# DWC_USB3 register map
Vendor: Texas Instruments
Registers are 32-bit, read-write, reset 0x0 unless marked. A register's access mark holds for its fields unless they carry their own. Offsets are as the file gives them; [hi:lo] are bit positions; {n}, {i} and the like mark numbered series; 'fields as' and 'values as' point back to an identical list.

## DWC_USB3 (part 2 of 2)
0xC188 USBOTGSS_GPRTBIMAP_FSLO access per field — Global port to USB instance mapping register, full/low-speed, low bits [31:0]
  [3:0] BINUM1 rw — FS USB instance number for port number 1 Application-programmable ID field
0xC18C USBOTGSS_GPRTBIMAP_FSHI ro — Global port to USB instance mapping register, full/low-speed, high bits [63:32]
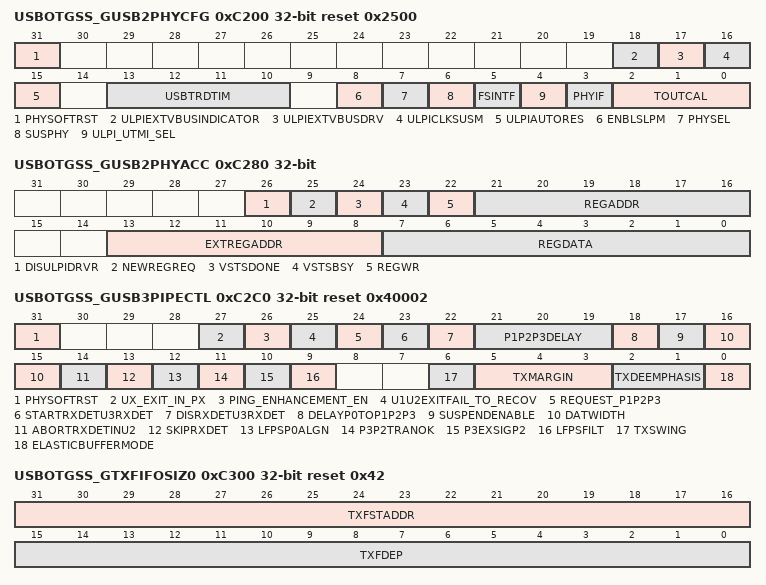
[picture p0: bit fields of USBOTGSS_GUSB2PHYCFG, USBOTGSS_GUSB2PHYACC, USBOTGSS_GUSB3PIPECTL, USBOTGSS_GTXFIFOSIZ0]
0xC200 USBOTGSS_GUSB2PHYCFG access per field reset 0x2500 — Global USB2 (UTMI/ULPI) PHY configuration
  [31] PHYSOFTRST rw — PHY Soft Reset. Active-high, fully static software reset for UTMI USB2 transceiver.
    0=inactive (Reset inactive.); 1=active (Reset active.)
  [18] ULPIEXTVBUSINDICATOR rw — ULPI External VBUS Indicator Indicates the ULPI PHY VBUS over-current indicator.
    0=int (PHY uses an internal VBUS valid comparator.); 1=ext (PHY uses an external VBUS valid comparator.)
  [17] ULPIEXTVBUSDRV rw — ULPI External VBUS Drive Selects supply source to drive 5V on VBUS, in the ULPI PHY.
    0=int (PHY drives VBUS with internal charge pump); 1=ext (PHY drives VBUS with an external supply.)
  [16] ULPICLKSUSM rw — Sets the ClockSuspendM bit in the Interface Control register on the ULPI PHY. Applicable only in serial FS/LS or Carkit modes. NOT APPLICABLE
  [15] ULPIAUTORES rw — ULPI Auto Resume. Sets the AutoResume bit in Interface Control register on the ULPI PHY.
    0=no (PHY does not use the AutoResume feature.); 1=auto (PHY uses the AutoResume feature.)
  [13:10] USBTRDTIM rw — USB 2.0 Turnaround Time, in PHY clock cycles. Specifies the response time for a MAC request to the Packet FIFO Controller (PFC) to fetch data from the DFIFO (SPRAM).
  [8] ENBLSLPM rw — Enable UTMI Sleep. Controls assertion of utmi_sleep_n, utmi_l1_suspend_n outputs to the PHY when in the L1 state.
    0=no (utmi_sleep_n, utmi_l1_suspend_n assertion from the core not transferred to the external PHY.); 1=yes (utmi_sleep_n, utmi_l1_suspend_n assertion from the core transferred to the external PHY.)
  [7] PHYSEL ro — PHY Select. (HS vs. serial): Unused, since serial PHY is not supported.
  [6] SUSPHY rw — Suspend enable for USB2.0 HS/FS/LS PHY (ULPI or UTMI). Set to 1 only after core initialization is complete.
    0=USB2.0 PHY not placed in Suspend mode; 1=USB2.0 PHY enters Suspend mode if port is suspended or unused
  [5] FSINTF ro — Full-Speed Serial Interface Select. UNUSED.
  [4] ULPI_UTMI_SEL rw — ULPI or UTMI+ Select
    0=UTMI+ Interface; 1=ULPI Interface
  [3] PHYIF rw — PHY Interface. DO NOT USE. If UTMI+ is selected, configures 8- or 16-bit interface. If ULPI is selected, configures SDR or DDR mode.
    0=zero (8-bit UTMI @60 MHz / SDR (12-pin) ULPI); 1=one (16-bit UTMI @30 MHz, not supported / DDR (8-pin) ULPI, not supported)
  [2:0] TOUTCAL rw — HS/FS Timeout Calibration. The number of PHY clocks, as indicated by the application in this field, is multiplied by a bit-time factor; this factor is added to the high-speed/full-speed interpacket timeout duration in the core to account for additional delays introduced by the PHY. This may be required, since the delay introduced by the PHY in generating the linestate condition may vary among PHYs. The USB standard timeout value for high-speed operation is 736 to 816 (inclusive) bit times. The USB standard timeout value for full-speed operation is 16 to 18 (inclusive) bit times. The application must program this field based on the speed of connection. The number of bit times added per PHY clock are: High-speed operation: 8 bit times per 60-MHz PHY clock cycle Full-speed operation: (depending on clock speed) 0.2 bit times per 60-MHz PHY clock cycle 0.25 bit times per 48-MHz PHY clock cycle
0xC280 USBOTGSS_GUSB2PHYACC access per field — Global USB2 PHY access
  [26] DISULPIDRVR ro — Disable ULPI drivers, for carkit mode. Auto-cleared. NOT USED.
  [25] NEWREGREQ rw — New register request. Auto-cleared.
    0=No_action; 1=Request_new_register_access; 1=Access_request_pending; 0=No_request_pending
  [24] VSTSDONE ro — VStatus Done
    1=access_is_done; 0=NEWREGREQ_0 (Application has set the NEWREGREQ bit, access is not done.)
  [23] VSTSBSY ro — VStatus busy
    1=Access_is_in_progress; 0=Access_is_done
  [22] REGWR rw — Register write
    0=Read; 1=Write
  [21:16] REGADDR rw — Register address ULPI PHY register address for immediate PHY register set access. Set to 6'h2F for extended PHY register set access.
  [13:8] EXTREGADDR rw — ULPI: PHY extended register address. UTMI+: Unused
  [7:0] REGDATA rw — Register data (read and write data)
0xC2C0 USBOTGSS_GUSB3PIPECTL access per field reset 0x40002 — Global USB3 PIPE control
  [31] PHYSOFTRST rw — PHY Soft Reset. Active-high, fully static software reset for PIPE USB3 transceiver.
    0=inactive (Reset inactive.); 1=active (Reset active.)
  [27] UX_EXIT_IN_PX rw — Workaround for SS PHY injecting a glitch on RxElecIdle while receiving Ux exit LFPS, and PowerDown change is in progress.
    0=default (U1/U2/U3 exit done in PHY power state P0); 1=wa (U1/U2/U3 exit done in PHY power state P1/P2/P3 respectively)
  [26] PING_ENHANCEMENT_EN rw — Ping Enhancement Enable: Extended downstream port U1 ping receive timeout. Invalid for Upstream port.
    0=default (U1 ping rx timeout is 300 ms (default)); 1=U1 ping rx timeout extended to 500 ms
  [25] U1U2EXITFAIL_TO_RECOV rw — Enhancement to prevent interoperability issue in case of incorrect LFPS handshake by the remote link.
    0=default (LTSSM goes to SS Inactive when U1/U2 LFPS handshake fails (default)); 1=enhanced (LTSSM goes to Recovery when U1/U2 LFPS handshake fails, and to SS.Inactive only if recovery fails.)
  [24] REQUEST_P1P2P3 rw — Control the systematic request of P1/P2/P3 for U1/U2/U3
    0=none (No P1/P2/P3 change request upon immediate Ux exit (remotely or locally initiated)); 1=Always request transition from P0 to P1/P2/P3 on PHY during transition from U0 to U1/U2/U3 on USB
  [23] STARTRXDETU3RXDET rw — Manual control for periodic Rx detection required in U3 and Rx.Detect, host mode.
    0=noop (No action); 1=detect (Trigger immediate Rx detection on transmitter.)
  [22] DISRXDETU3RXDET rw — Disable the HW-scheduled periodic Rx detection required in U3 and SS.Disabled, for host mode.
    0=Auto (Rx detection is HW-scheduled every 12/100 ms when in SS.Disabled / U3 LTSSM state, respectively. This requires the suspend clock to run permanently.); 1=Manual (HW-scheduled Rx detection is disabled, and must be SW-controlled using DoRxDetect.)
  [21:19] P1P2P3DELAY rw — If DelayP0toP1P2P3=1, delays the transition to P1/P2/P3 when entering U1/U2/U3 until P1P2P3Delay*8b10b errors occur, or RxValid=0 on PIPE.
  [18] DELAYP0TOP1P2P3 rw — Delay PHY change from P0 to P1/P2/P3 when link state changes from U0 to U1/U2/U3, respectively.
    0=dis (When entering U1/U2/U3, transition to P1/P2/P3 without checking RxElecIlde, RxValid on PIPE.); 1=en (When entering U1/U2/U3, delay the transition to P1/P2/P3 until RxElecIlde=1, RxValid=0 on PIPE)
  [17] SUSPENDENABLE rw — Suspend Enable for USB3.0 SS PHY. Set to 1 only after core initialization is complete.
    0=USB3.0 PHY not placed in Suspend mode; 1=USB 3.0 PHY enters Suspend mode when conditions are valid
  [16:15] DATWIDTH ro — PIPE Data Width (input from phy: refer to PIPE standard) Field updated to the input's value immediately after reset.
    2=DATWIDTH_2_r (PIPE data is 8 bit @500 MHz); 1=DATWIDTH_1_r (PIPE data is 16 bit @250 MHz); 0=DATWIDTH_0_r (PIPE data is 32 bit @125 MHz)
  [14] ABORTRXDETINU2 rw — Abort Rx Detect in U2. For Downstream port only.
    0=no_abort (Receiver detection not aborted); 1=abort (When in U2, receiver detection will be aborted if U2 exit LFPS is received.)
  [13] SKIPRXDET rw — Skip Rx Detect. When set, the core skips Rx Detection if PIPE signal 'RxElecIdle' is low. Skip is defined as waiting for the appropriate timeout, then repeating the operation.
  [12] LFPSP0ALGN rw — LFPS P0 Align. When set to 1: - The core deasserts LFPS transmission on the clock edge that it requests PHY power state 0 when exiting U1, U2, or U3 low power states. Otherwise, LFPS transmission is asserted one clock earlier. - The core requests symbol transmission two pipe_rx_pclks periods after the PHY asserts PhyStatus as a result of the PHY switching from P1 or P2 state to P0 state.
    0=def (Default); 1=align (DO NOT USE)
  [11] P3P2TRANOK rw — P3-to-P2 Transitions OK
    0=notset (P0 is always entered as an intermediate state during transitions between P2 and P3, as defined in the PIPE specification.); 1=set (Core transitions directly from PHY power state P2 to P3 or from state P3 to P2. Illegal as per PIPE, use only if PHY cannot do LFPS in P3.)
  [10] P3EXSIGP2 rw — PHY power state behaviour upon U3 exit handshake.
    0=Default behaviour; 1=p2 (Go to P2 before attempting a U3 exit handshake.)
  [9] LFPSFILT rw — LFPS Filter. When set, filter LFPS reception with PIPE 'RxValid' signal in PHY power state P0, that is, ignore LFPS reception from the PHY unless both PIPE signals 'RxElecIdle' and 'RxValid' are deasserted.
  [6] TXSWING rw — Tx Swing (output to PHY: refer to PIPE standard)
  [5:3] TXMARGIN rw — Tx Margin[2:0] (output to PHY: refer to PIPE standard)
  [2:1] TXDEEMPHASIS rw — Tx Deemphasis (output to PHY: refer to PIPE standard) The value driven to the PHY is controlled by the LTSSM during USB3 Compliance mode.
  [0] ELASTICBUFFERMODE rw — Elastic Buffer Mode (output to PHY: refer to PIPE standard)
0xC300 USBOTGSS_GTXFIFOSIZ0 reset 0x42 — Global Transmit FIFO Size 0: FIFO mapping in RAM1, from staddr to (staddr+dep-1)
  [31:16] TXFSTADDR — Transmit FIFO RAM start address, in 64-bit RAM words.
    0=Minimum_(RAM1_base); 0x760=Maximum_(up_to_RAM1_depth_-_32)
  [15:0] TXFDEP — Transmit FIFO depth, in 64-bit RAM words.
    0x780=Maximum_depth_(the_whole_buffer); 32=Minimum_depth
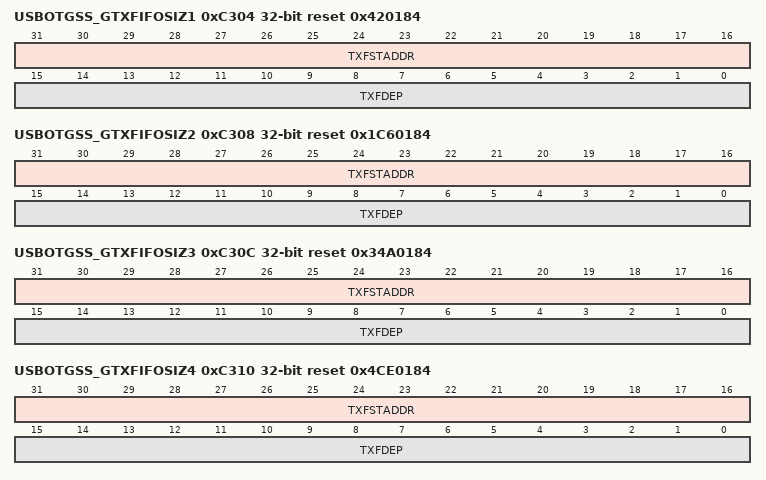
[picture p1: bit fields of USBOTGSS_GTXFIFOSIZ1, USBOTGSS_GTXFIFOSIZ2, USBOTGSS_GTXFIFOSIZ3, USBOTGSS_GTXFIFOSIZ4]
0xC304 USBOTGSS_GTXFIFOSIZ1 reset 0x420184 — Global Transmit FIFO Size 1: FIFO mapping in RAM1, from staddr to (staddr+dep-1)
  fields as USBOTGSS_GTXFIFOSIZ0
0xC308 USBOTGSS_GTXFIFOSIZ2 reset 0x1C60184 — Global Transmit FIFO Size 2: FIFO mapping in RAM1, from staddr to (staddr+dep-1)
  fields as USBOTGSS_GTXFIFOSIZ0
0xC30C USBOTGSS_GTXFIFOSIZ3 reset 0x34A0184 — Global Transmit FIFO Size 3: FIFO mapping in RAM1, from staddr to (staddr+dep-1)
  fields as USBOTGSS_GTXFIFOSIZ0
0xC310 USBOTGSS_GTXFIFOSIZ4 reset 0x4CE0184 — Global Transmit FIFO Size 4: FIFO mapping in RAM1, from staddr to (staddr+dep-1)
  fields as USBOTGSS_GTXFIFOSIZ0
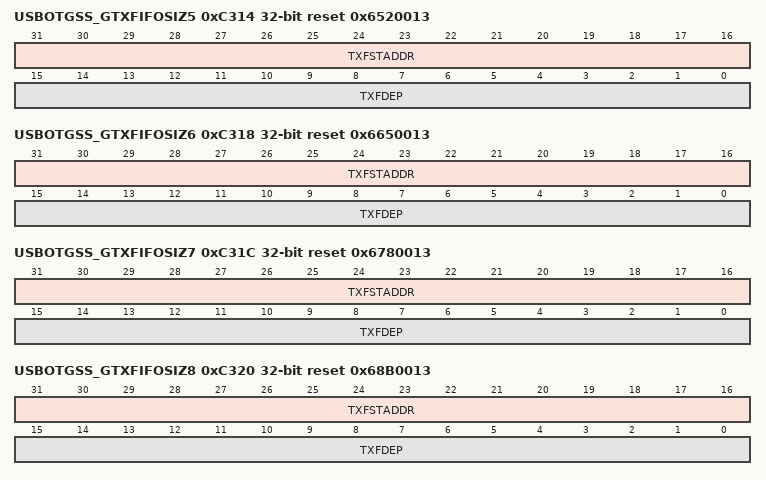
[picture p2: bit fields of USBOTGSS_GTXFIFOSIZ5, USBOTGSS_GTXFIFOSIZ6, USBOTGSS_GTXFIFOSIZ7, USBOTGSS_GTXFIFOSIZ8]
0xC314 USBOTGSS_GTXFIFOSIZ5 reset 0x6520013 — Global Transmit FIFO Size 5: FIFO mapping in RAM1, from staddr to (staddr+dep-1)
  fields as USBOTGSS_GTXFIFOSIZ0
0xC318 USBOTGSS_GTXFIFOSIZ6 reset 0x6650013 — Global Transmit FIFO Size 6: FIFO mapping in RAM1, from staddr to (staddr+dep-1)
  fields as USBOTGSS_GTXFIFOSIZ0
0xC31C USBOTGSS_GTXFIFOSIZ7 reset 0x6780013 — Global Transmit FIFO Size 7: FIFO mapping in RAM1, from staddr to (staddr+dep-1)
  fields as USBOTGSS_GTXFIFOSIZ0
0xC320 USBOTGSS_GTXFIFOSIZ8 reset 0x68B0013 — Global Transmit FIFO Size 8: FIFO mapping in RAM1, from staddr to (staddr+dep-1)
  fields as USBOTGSS_GTXFIFOSIZ0
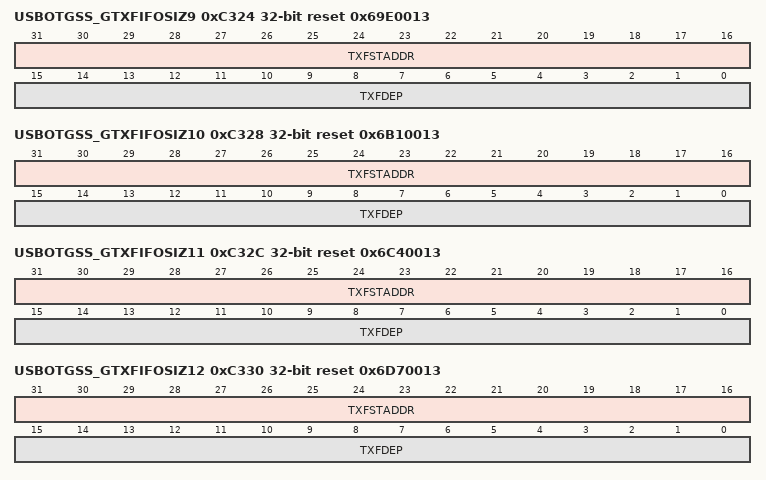
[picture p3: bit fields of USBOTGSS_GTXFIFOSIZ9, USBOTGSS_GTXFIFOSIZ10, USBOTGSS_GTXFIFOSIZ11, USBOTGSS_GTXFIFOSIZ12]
0xC324 USBOTGSS_GTXFIFOSIZ9 reset 0x69E0013 — Global Transmit FIFO Size 9: FIFO mapping in RAM1, from staddr to (staddr+dep-1)
  fields as USBOTGSS_GTXFIFOSIZ0
0xC328 USBOTGSS_GTXFIFOSIZ10 reset 0x6B10013 — Global Transmit FIFO Size 10: FIFO mapping in RAM1, from staddr to (staddr+dep-1)
  fields as USBOTGSS_GTXFIFOSIZ0
0xC32C USBOTGSS_GTXFIFOSIZ11 reset 0x6C40013 — Global Transmit FIFO Size 11: FIFO mapping in RAM1, from staddr to (staddr+dep-1)
  fields as USBOTGSS_GTXFIFOSIZ0
0xC330 USBOTGSS_GTXFIFOSIZ12 reset 0x6D70013 — Global Transmit FIFO Size 12: FIFO mapping in RAM1, from staddr to (staddr+dep-1)
  fields as USBOTGSS_GTXFIFOSIZ0
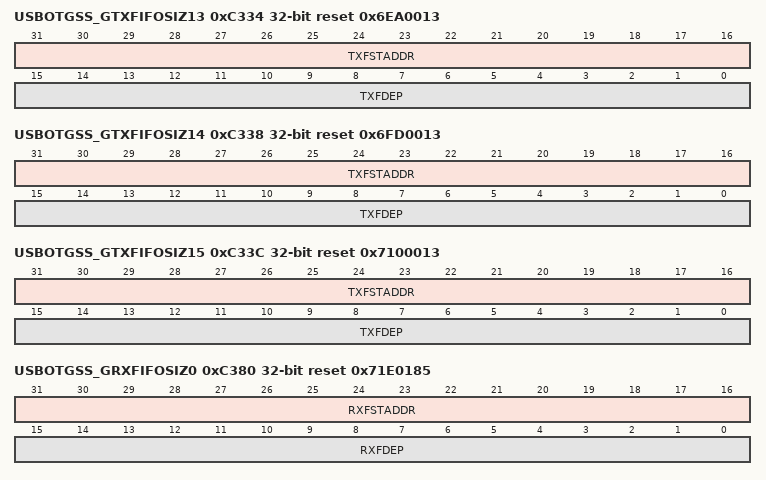
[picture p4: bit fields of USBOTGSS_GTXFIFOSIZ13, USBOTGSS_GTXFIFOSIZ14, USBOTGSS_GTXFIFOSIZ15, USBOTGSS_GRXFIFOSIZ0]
0xC334 USBOTGSS_GTXFIFOSIZ13 reset 0x6EA0013 — Global Transmit FIFO Size 13: FIFO mapping in RAM1, from staddr to (staddr+dep-1)
  fields as USBOTGSS_GTXFIFOSIZ0
0xC338 USBOTGSS_GTXFIFOSIZ14 reset 0x6FD0013 — Global Transmit FIFO Size 14: FIFO mapping in RAM1, from staddr to (staddr+dep-1)
  fields as USBOTGSS_GTXFIFOSIZ0
0xC33C USBOTGSS_GTXFIFOSIZ15 reset 0x7100013 — Global Transmit FIFO Size 15: FIFO mapping in RAM1, from staddr to (staddr+dep-1)
  fields as USBOTGSS_GTXFIFOSIZ0
0xC380 USBOTGSS_GRXFIFOSIZ0 reset 0x71E0185 — Global Receive FIFO Size 0: FIFO mapping in RAM0, from staddr to (staddr+dep-1)
  [31:16] RXFSTADDR — Receive FIFO RAM Start Address, in 64-bit RAM words.
    0=min (Minimum (RAM0 base)); 0x3C2=max (Maximum (base of descriptor cache in RAM0 - 32))
  [15:0] RXFDEP — Receive FIFO Depth, in 64-bit RAM words
    32=min (Minimum depth); 0x3E2=max (Maximum depth (the whole buffer))
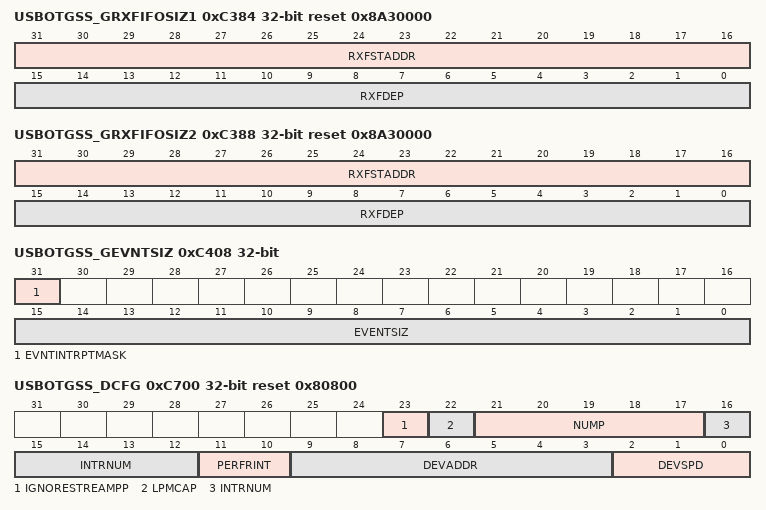
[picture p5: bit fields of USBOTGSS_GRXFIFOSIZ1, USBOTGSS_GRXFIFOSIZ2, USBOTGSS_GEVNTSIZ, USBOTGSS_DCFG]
0xC384 USBOTGSS_GRXFIFOSIZ1 reset 0x8A30000 — Global receive FIFO size 1: FIFO mapping in RAM0, from staddr to (staddr+dep-1)
  fields as USBOTGSS_GRXFIFOSIZ0
0xC388 USBOTGSS_GRXFIFOSIZ2 reset 0x8A30000 — Global receive FIFO size 2: FIFO mapping in RAM0, from staddr to (staddr+dep-1)
  fields as USBOTGSS_GRXFIFOSIZ0
0xC400 USBOTGSS_GEVNTADRLO — Global event address: Lower 32 bits of start address of the external memory for the event buffer. During operation, hardware does not update this address.
  [31:0] EVNTADRLO — EVNTADR[31:0]
0xC404 USBOTGSS_GEVNTADRHI — Global event address: Upper 32 bits of start address of the external memory for the event buffer. During operation, hardware does not update this address.
  [31:0] EVNTADRHI — EVNTADR[64:32]
0xC408 USBOTGSS_GEVNTSIZ access per field — Global event buffer size
  [31] EVNTINTRPTMASK rw — Event interrupt mask Prevents the interrupt from being generated when set to 1 The events are queued wven when the mask is set.
  [15:0] EVENTSIZ rw — Event buffer size Size of the event buffer in bytes; must be a multiple of 4. Programmed by software once during initialization.
0xC40C USBOTGSS_GEVNTCOUNT access per field — Global event buffer count
  [15:0] EVNTCOUNT rw — Event count When read, returns the number of valid events in the event buffer in bytes When written, hardware decrements the count by the value written. The interrupt remains active while count is not 0.
0xC600 USBOTGSS_GHWPARAMS8 ro reset 0x71E — Global hardware parameters 8
  [31:0] DWC_USB3_DCACHE_DEPTH_INFO — Depth of data cache, in 64-bit words (fixed). The cache occupies RAM0 from word 0 to DCACHE_DEPTH_INFO-1: Rx FIFOs shall be mapped from word DCACHE_DEPTH_INFO to RAM0_DEPTH-1.
0xC604 USBOTGSS_GHWPARAMS9 ro — Global hardware parameters 9
  [31:0] GHWPARAMS9 — NOT USED
0xC700 USBOTGSS_DCFG reset 0x80800 — Device configuration: Configures the core in device mode after power-on or after certain control commands or enumeration. Does not change after initial programming.
  [23] IGNORESTREAMPP — Ignore Packet-Pending for Stream management. From stream-capable bulk endpoints only.
    0=nochange (When Data Packet is received with PP=0 (OUT EP) or ACK is received with NumP=0 and PP=0 (IN EP), search another stream (CStream) to initiate to the host. This is non-optimal a) When host sets PP=0 even though it has not finished with the stream, and b) if the EP is configured with one transfer resource i.e. can't initiate another stream.); 1=ignore (PP is ignored for stream selection, no another stream is searched when DP is received with (PP=0) or ACK with (NumP=0, PP=0), to enhance performance if system bus bandwidth is low or host responds to ERDY quickly.)
  [22] LPMCAP — Link Power Management (LPM) Capability.
    0=no (not LPM capable: device cannot respond to LPM transactions.); 1=yes (LPM capable: device shall respond to LPM transactions.)
  [21:17] NUMP — Number of Receive Buffers. Indicates number of receive buffers to be reported in ACK TP. Value based on RxFIFO size, buffer sizes programmed in descriptors, and system latency.
  [16:12] INTRNUM — Interrupt Number. Interrupt/EventQ number on which non-endpoint-specific device related interrupts (see DEVT) are generated.
  [11:10] PERFRINT — Periodic Frame Interrupt. Time within a (micro)frame when the application must be notified using the End Of Periodic Frame Interrupt, which can be used to determine if all the periodic (isochronous, interrupt) traffic for that (micro)frame is complete.
    0=80% of the (micro)frame interval; 1=85% of the (micro)frame interval; 3=95% of the (micro)frame interval; 2=90% of the (micro)frame interval
  [9:3] DEVADDR — Device Address. Configure upon set-address USB command, clear to 0 upon USB reset.
    0=def (Default address for unenumerated device.)
  [2:0] DEVSPD — Device Speed: USB speed at which the core should connect. Actual bus speed is determined only after chirp completion, based on the speed of the attached USB host.
    0=hs (High Speed (HS): 480 Mbit/s); 1=fs (Full Speed (FS): 12 Mbit/s); 3=fs_serial (Full Speed (FS): 12 Mbit/s on serial PHY: NOT SUPPORTED); 4=ss (Super Speed (SS): 5 Gbit/s); 2=ls_serial (Low Speed (LS): 1.5 Mbit/s on serial PHY: NOT SUPPORTED)
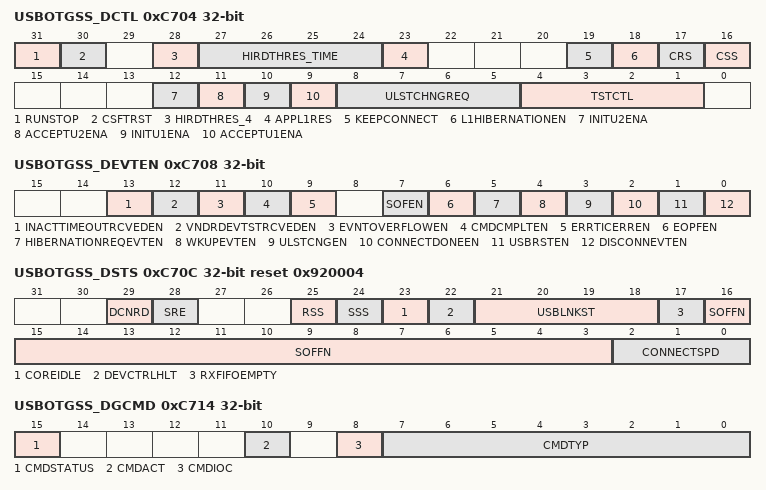
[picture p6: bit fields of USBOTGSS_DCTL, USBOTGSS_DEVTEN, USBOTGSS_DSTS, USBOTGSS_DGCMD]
0xC704 USBOTGSS_DCTL access per field — Device control
  [31] RUNSTOP rw
    0=Stop USB device controller operation and signal disconnect to attached host. Clear only after all active transfers have been removed. For USB 3.0 disconnection, proceed by changing the target state to RX_DET. [22] DEVCTRLHLT is set once disconect is complete and core is idle.; 1=Start USB device controller operation, after programming the device CSR. Controller will not signal connect to the attached host until the bit is set.
  [30] CSFTRST rw — Core Soft Reset. Auto-cleared. The reset has the following effect: - Interrupts are cleared. - Registers are cleared except: USBOTGSS_GSTS, USBOTGSS_GSNPSID, USBOTGSS_GGPIO, USBOTGSS_GUID, USBOTGSS_GUSB2PHYCFG, USBOTGSS_GUSB3PIPECTL, USBOTGSS_DCFG, USBOTGSS_DCTL, USBOTGSS_DEVTEN, USBOTGSS_DSTS. TxFIFOs and RxFIFO are flushed. - State machines are reset to the idle state, except the device slave. - Transactions on the device bus Master are terminated after completion. - Transactions on the USB are terminated immediately.
    1=reset (Start reset (self-clearing)); 1=active (Reset ongoing); 0=idle (No ongoing reset, reset complete.)
  [28] HIRDTHRES_4 rw — Host Initiated Resume Duration (HIRD) Threshold, MSbit: See HIRDTHRES_TIME
  [27:24] HIRDTHRES_TIME rw — Host Initiated Resume Duration (HIRD) Threshold, LSBits = timeout value. utmi_l1_suspend_n is asserted in L1 when : (HIRD value &gt;= HIRDTHRES_TIME) and (HIRDTHRES_4=1) utmi_sleep_n is asserted in L1 when : (HIRD value &lt; HIRDTHRES_TIME) or (HIRDTHRES_4=0)
    6=510 us; 1=135 us; 10=810 us; 7=585 us; 0=60 us; 2=210 us; 8=660 us; 9=735 us; 11=885 us; 4=360 us; 5=435 us; 12=960 us (maximum: higher values are invalid); 3=285 us
  [23] APPL1RES rw — LPM Response Programmed by Application: Handshake response made to LPM token. Note that if USBOTGSS_DCFG[22] LPMCAP = 0, the response is always timeout (no response).
    0=can_nyet (NYET handshake to correct LPM transaction if data is pending in Tx FIFO or if OUT (Rx) endpoints are in flow controlled state.); 1=ack (Core shall ACK correct LPM transaction regardless of Tx FIFO status and OUT (Rx) endpoint flow control.)
  [19] KEEPCONNECT rw — Used for Save-and-Restore operation. DO NOT USE, SAR NOT IMPLEMENTED
    0=noaction; 1=keep (Prevents device disconnection when RUNSTOP is cleared to 0. Enables the 'Hibernation Request Event' when the link goes to U3/L2. Prevents LTSSM from automatically going to U0/L0 when host requests resume from U3/L2.)
  [18] L1HIBERNATIONEN rw — DO NOT USE, SAR NOT IMPLEMENTED
  [17] CRS rw — Controller Restore State. DO NOT USE, SAR NOT IMPLEMENTED
    0=restore (Initiate restore process, sets[25] RSS to 1); 1=noaction
  [16] CSS rw — Controller Save State. DO NOT USE, SAR NOT IMPLEMENTED
    0=save (Initiate save process, sets[24] SSS to 1); 1=noaction
  [12] INITU2ENA rw — Initiate U2 Enable. Cleared to 0 by USB reset.
    0=newEnum1 (May not initiate U2); 1=newEnum2 (May initiate U2)
  [11] ACCEPTU2ENA rw — Accept U2 Enable. Cleared to 0 by USB reset.
    0=no (Reject U2 except when Force_LinkPM_Accept bit is set); 1=yes (Accept transition to U2 state if nothing is pending on the application side)
  [10] INITU1ENA rw — Initiate U1 Enable. Cleared to 0 by USB reset.
    0=no (May not initiate U1); 1=yes (May initiate U1)
  [9] ACCEPTU1ENA rw — Accept U1 Enable. Cleared to 0 by USB reset.
    0=no (Reject U1 except when Force_LinkPM_Accept bit is set); 1=yes (Accept transition to U1 state if nothing is pending on the application side.)
  [8:5] ULSTCHNGREQ rw — USB/Link State Change Request. A new request is indicated by a change of value. To issue the same request back-to-back, a 0 shall be written between the two requests. State change request result is reflected inUSBOTGSS_DSTS.
    6=inact (SS: SS.Inactive); 8=rec (SS: Recovery HS/FS/LS: Remote wakeup request. Issue only when device is in early suspend or suspend state); 5=rxdet (SS: Rx.Detect); 10=comp (SS: Compliance); 11=loop (SS: Loopback); 0=noop (No action); 4=dis (SS: SS.Disabled)
  [4:1] TSTCTL rw — Test Control
    1=Test_J mode; 0=Test mode disabled; 2=Test_K mode; 4=Test_Packet mode; 5=Tes_Force_Enable mode; 3=Test_SE0_NAK mode
0xC708 USBOTGSS_DEVTEN access per field — Device event enable: Enables the generation of device-specific events (see USBOTGSS_DEVT).
  [13] INACTTIMEOUTRCVEDEN rw — U2 Inactive Timeout Received Event Enable
  [12] VNDRDEVTSTRCVEDEN rw — Vendor Device Test Received event Enable
  [11] EVNTOVERFLOWEN rw — Event Overflow event Enable
  [10] CMDCMPLTEN rw — Command Complete event Enable
  [9] ERRTICERREN rw — Erratic Error event Enable
  [7] SOFEN rw — Start of (micro)Frame event Enable. For debug only.
  [6] EOPFEN rw — End of Periodic Frame event Enable. For debug only.
  [5] HIBERNATIONREQEVTEN rw — Hibernation Request Event Enable. DO NOT USE, HIBERNATION NOT IMPLEMENTED
  [4] WKUPEVTEN rw — Resume/Remote Wakeup Detected Event Enable.
  [3] ULSTCNGEN rw — USB/Link State Change event Enable
  [2] CONNECTDONEEN rw — Connection Done event Enable
  [1] USBRSTEN rw — USB Reset Enable
  [0] DISCONNEVTEN rw — Disconnct Event Enable
0xC70C USBOTGSS_DSTS ro reset 0x920004 — Device status
  [29] DCNRD — Device Controller Not Ready
    1=wait (Core is completing the state transitions after hibernation exit. Wait before processing USBLNKST); 0=rdy (Core is ready.)
  [28] SRE — Save/Restore Error. NOT SUPPORTED.
  [25] RSS — Restore State Status, triggered by writing 1 to RSS
    1=restoring (Restore is ongoing); 0=idle (Restore is complete / inactive)
  [24] SSS — Save State Status, triggered by writing 1 to CSS
    1=saving (Save is ongoing); 0=idle (Save is complete / inactive)
  [23] COREIDLE — Core Idle status. asserted when all RxFIFO data transferred to system memory, all completed descriptors are written, and all Event Counts are zero. Changes after reset, so that reset value may not match first readout.
    1=idle (core is idle); 0=active (core has unfinished activities)
  [22] DEVCTRLHLT — Device Controller Halted. Cleared (0) when theUSBOTGSS_DCTL[31] RUNSTOP is written to 1. Set (1) after USBOTGSS_DCTL[31] RUNSTOP has been written to 0, core is idle and disconnect process is complete. When DEVCTRLHLT =1, no Device events are generated.
  [21:18] USBLNKST — USB/Link State. Encoding depends on the connection speed (SS or HS/FS/LS)
    3=USBLNKST_3_r (SS: LTSSM = U3 HS/FS/LS: Suspend state); 14=USBLNKST_14_r (HS/FS/LS: Reset); 4=USBLNKST_4_r (SS: LTSSM = SS_DIS HS/FS/LS: Disconnected state (default)); 11=USBLNKST_11_r (SS: LTSSM = LPBK); 15=USBLNKST_15_r (SS: LTSSM = Reset/Resume. USB resume or reset received from the host while in suspend. Write RECOV=8 to[8:5] ULSTCHNGREQ field to acknowledge it. HS/FS/LS: Resume); 2=USBLNKST_2_r (SS: LTSSM = U2 HS/FS/LS: Sleep state); 0=USBLNKST_0_r (SS: LTSSM = U0 HS/FS/LS: On state); 10=USBLNKST_10_r (SS: LTSSM = CMPLY); 6=USBLNKST_6_r (SS: LTSSM = SS_INACT); 1=USBLNKST_1_r (SS: LTSSM = U1); 8=USBLNKST_8_r (SS: LTSSM = RECOV); 7=USBLNKST_7_r (SS: LTSSM = POLL); 9=USBLNKST_9_r (SS: LTSSM = HRESET); 5=USBLNKST_5_r (SS: LTSSM = RX_DET HS/FS/LS: Early Suspend state)
  [17] RXFIFOEMPTY
    1=empty (Rx FIFO is empty); 0=notempty (Rx FIFO is not empty)
  [16:3] SOFFN — received Start Of Frame's Frame Number
  [2:0] CONNECTSPD — Connection Speed. USB speed at which the device has come up after speed detection through a chirp sequence.
    3=fs_serial (Full Speed (FS): 12 Mbit/s on serial PHY: NOT SUPPORTED); 2=ls_serial (Low Speed (LS): 1.5 Mbit/s on serial PHY: NOT SUPPORTED); 1=fs (Full Speed (FS): 12 Mbit/s); 0=hs (High Speed (HS): 480 Mbit/s); 4=ss (Super Speed (SS): 5 Gbit/s)
0xC710 USBOTGSS_DGCMDPAR — Device generic command parameter: To be programmed before or along with the device command itself.
  [31:0] PARAMETER — Parameter of the command; command-dependent.
0xC714 USBOTGSS_DGCMD access per field — Device generic command: Generic command interface to send link management packets and notifications.
  [15] CMDSTATUS ro — Command Status.
    1=newEnum2 (CmdErr: Error while processing the command.); 0=none (No error)
  [10] CMDACT rw — Command active. Auto-cleared.
    1=Start generic command execution (self-clearing); 1=active (Command active (ongoing)); 0=idle (No ongoing command, command complete.)
  [8] CMDIOC wo — Command Interrupt On Complete. Event mapped to interrupt numberUSBOTGSS_DCFG[16:12] INTNUM. Reads return 0.
    1=ioc (Generic Command Completion event to be issued after executing the command.)
  [7:0] CMDTYP wo — Command Type. Reads return 0.
    12=CMDTYP_12_w (Set Endpoint NRDY: Makes the core think that the given endpoint is in an NRDY state. If buffers are available in that endpoint, an ERDY is immediately transmitted. Parameter[4:0] = Physical Endpoint Number); 3=CMDTYP_3_w (Transmit Function Wake Device Notification (Notification-only in SuperSpeed) Parameter[7:0] - Interface Number (IntfNum) that caused remote wakeup); 6=CMDTYP_6_w (Transmit Function Host Role Request Device Notification (Notification-only in SuperSpeed) Parameter[1:0] = RSP Phase (Notification Type Specific) is INITIATE (2'b01) or CONFIRM (2'b10).); 10=CMDTYP_10_w (All FIFO Flush. (No parameter)); 2=CMDTYP_2_w (Set Periodic Parameters Parameter[9:0] (SystemExitLatency): Set value programmed by the host through the Set SEL device request, in microseconds. The Set SEL control transfer has 6 bytes of data and contains 4 values; Refer to the USB 3.0 spec, Section 9.4.12. Offset / Name / Meaning: 0 U1SEL Time in us for U1 System Exit Latency 1 U1PEL Time in us for U1 Device to Host Exit Latency 2 U2SEL Time in us for U2 System Exit Latency 4 U2PEL Time in us for U2 Device to Host Exit Latency If the device is enabled for U1 and U2, then the U2PEL should be programmed. If the device is enabled only for U1, then U1PEL should be programmed into this parameter. If the value is greater than 125 us, then the software must program a value of zero into this register.); 1=CMDTYP_1_w (Transmit Set Link Function LPM. (Reserved in non-SuperSpeed operations) Parameter[0] = [Force_LinkPM_Accept] (0: De-assert 1: Assert)); 9=CMDTYP_9_w (Selected FIFO Flush Parameter[4:0] = FIFO Number Paramer[5] = TX FIFO (1) or RX FIFO (0)); 16=CMDTYP_16_w (Run device Bus LoopBack Test: Issue this command first, then the Start Transfer command to EP 0 and 1. Configure EP0 as OUT and EP1 as IN. The core reads data from the IN buffers and writes it back to OUT buffers. The IN and OUT must have an equal amount of data buffer. The endpoint 1 Tx-FIFO default value of (512/8)+2 = 66 should be changed to (1024/8)+2 = 130 for loopback mode. Parameter[0] = enable (1) and disable (0) Loopback mode.)
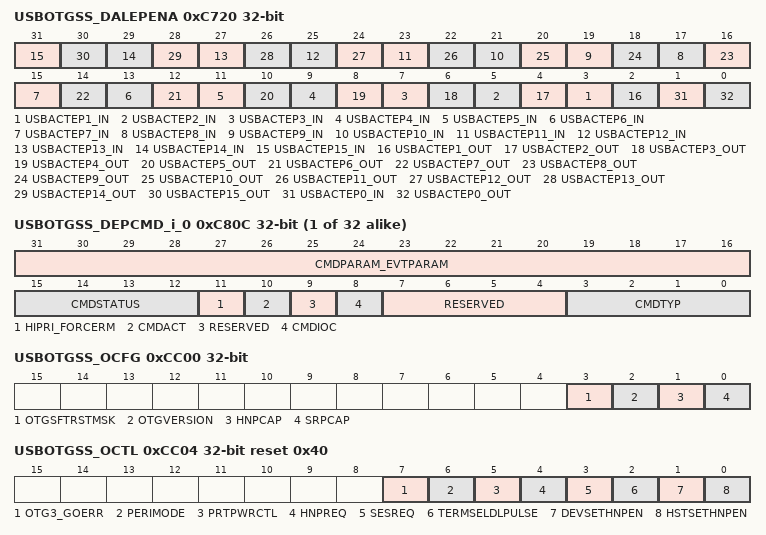
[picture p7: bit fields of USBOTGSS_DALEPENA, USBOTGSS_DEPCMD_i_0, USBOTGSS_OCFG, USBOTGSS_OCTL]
0xC720 USBOTGSS_DALEPENA — Device active USB endpoint enable. Set each bit (1) to enable the corresponding endpoint. Bits 0 and 1 are set after USB reset as they enable the control endpoint. All other bits are set according to enumeration, and cleared on a USB reset.
  [2n+1] USBACTEP{n}_IN (n=1..15) — USB Activate Endpoint {n} IN
  [2n] USBACTEP{n}_OUT (n=1..15) — USB Activate Endpoint {n} OUT
  [1] USBACTEP0_IN — USB Activate Endpoint 0 IN (control)
  [0] USBACTEP0_OUT — USB Activate Endpoint 0 OUT (control)
{0xC800+0x10*i} USBOTGSS_DEPCMDPAR2_i_{i} (i=0..31) — Device physical endpoint-n command parameter 2. Must be programmed before issuing the command, if required by the command.
  [31:0] PARAMETER2 — Command-dependent
{0xC804+0x10*i} USBOTGSS_DEPCMDPAR1_i_{i} (i=0..31) — Device physical endpoint-n command parameter 1 Must be programmed before issuing the command, if required by the command.
  [31:0] PARAMETER1 — Command-dependent
{0xC808+0x10*i} USBOTGSS_DEPCMDPAR0_i_{i} (i=0..31) — Device physical endpoint-n command parameter 0 Must be programmed before issuing the command.
  [31:0] PARAMETER0 — Command-dependent
{0xC80C+0x10*i} USBOTGSS_DEPCMD_i_{i} (i=0..31) — Device physical endpoint-n command
  [31:16] CMDPARAM_EVTPARAM — Read: Event parameters (see, ). Write: Command parameters (see , ) command-dependent: DEPSTRTXFER on isoc EP: [31:16] microframe number for the first TRB (StartMicroFramNum) DEPSTRTXFER on stream-capable EP: [31:16] USB stream ID for the transfer (StreamID) DEPUPDXFER/DEPENDXFER: [22:16] Transfer resource index returned by HW upon transfer start (XferRscIdx) DEPSTARTCFG: [22:16] Transfer resource index assigned by software upon new configuration start (XferRscIdx)
  [15:12] CMDSTATUS — Command Completion Status. Additional information about the command completion. Same format as bits 15:12 of the Endpoint Command Complete event.
  [11] HIPRI_FORCERM — HighPriority/ForceRM. Write-only field, reads return 0. Start Transfer command: HighPriority value End Transfer command: ForceRM value
    0=HighPriority/ForceRM=0; 1=HighPriority/ForceRM=1
  [10] CMDACT — Command Active. Auto-cleared.
    1=Execute_the_generic_command; 1=Command_execution_is_being_started; 0=CMDACT_0_r (Endpoint is ready to accept another command, CmdStatus field is valid. The effects of the previously-issued command may not all have taken place yet.)
  [9] RESERVED — Register is stored in RAM, so that the field is actually writable (value is still don't care).
  [8] CMDIOC — Command Interrupt On Complete. Event mapped to interrupt number DEPCFG.IntNum (the command). Reads return 0.
    0=No_interrupt_on_complete; 1=CMDIOC_1_w (generic Endpoint Command Complete event issued after executing the command.)
  [7:4] RESERVED — Register is stored in RAM, so that the field is actually writable (value is still don't care).
  [3:0] CMDTYP — Command Type.
    4=DEPSETSTALL:_Set_Stall_(No_Parameter); 3=DEPGETDSEQ:_3 (DEPGETDSEQ: Get Data Sequence Number (No Parameter)); 6=DEPSTRTXFER:_6 (DEPSTRTXFER: Start Transfer (64-bit parameter)); 2=DEPXFERCFG:_2 (DEPXFERCFG: Set Endpoint Transfer Resource Configuration (32-bit parameter)); 8=DEPENDXFER:_End_Transfer_(No_Parameter); 1=DEPCFG:_1 (DEPCFG: Set Endpoint Configuration (64-bit parameter)); 9=DEPSTARTCFG:_9 (DEPSTARTCFG: Start New Configuration (No Parameter)); 5=DEPCSTALL:_Clear_Stall_(No_Parameter); 7=DEPUPDXFER:_7 (DEPUPDXFER: Update Transfer (No Parameter))
0xCC00 USBOTGSS_OCFG access per field — OTG configuration
  [3] OTGSFTRSTMSK rw — Protects OTG, PHY and VBUS filters from the following software resets: xHCIUSBOTGSS_USBCMD[1] HCRST (host), USBOTGSS_DCTL[30] CSFTRST (device). Note: In OTG2 applications, it is not recommended to program USBOTGSS_USBCMD[1] HCRST during role switch.
    0=default (OTG logic reset by software resets); 1=mask (OTG logic not affected by software resets. Use only with[13:12] PRTCAPDIR = 0x3)
  [2] OTGVERSION rw — Debug, always write 0.
  [1] HNPCAP rw — HNP Capabilty Enable.
    0=no (HNP capability is disabled); 1=yes (HNP capability is enabled)
  [0] SRPCAP rw — SRP Capability enable. For A-device, SRP detection. For B-device, SRP generation.
    0=no (SRP capability is disabled); 1=yes (SRP capability is enabled)
0xCC04 USBOTGSS_OCTL access per field reset 0x40 — OTG control IMPORTANT NOTE: Register is reinitialized on ID change, but is not affected by a software reset.
  [7] OTG3_GOERR rw — To be set upon TRSP_ACK_ERR, TRSP_CNF_ERR, or TRSP_WRST_ERR timeout. Auto-cleared. OTG3: NOT IMPLEMENTED, DO NOT SET.
    0=noop; 1=pending (LTSSM transition to error state is pending); 1=go (Sends LTSSM to error state during OTG 3.0 RSP)
  [6] PERIMODE rw — Peripheral Mode. Program the core to work as a peripheral or as a host.
    1=yes (OTG device acts as a peripheral); 0=no (OTG device acts as a host)
  [5] PRTPWRCTL rw — Port Power Control. Set or cleared by software. Self-cleared in any of the following conditions: 1) transition to a_idle OTG state 2) aidl_bdis_tout event when in a_suspend OTG state 3) a_wait_bcon_tout event when in a_wait_bcon OTG state 4) transition to any b_* OTG state
    0=swoff (Manually switch off VBUS drive.); 1=req (Initiate the VBUS drive on the USB, when A-device.); 1=on (VBUS is driven.); 0=off (VBUS drive is off)
  [4] HNPREQ rw — HNP Request. Set (1) by software to initiate HNP request to the connected USB host. Clear (0) by software upon eitherUSBOTGSS_OEVT[11] OTGBDEVHOSTENDEVNT or USBOTGSS_OEVT[8] OTGBDEVVBUSCHNGEVNT.
    0=done (HNP request inactive.); 1=ongoing (HNP request active.)
  [3] SESREQ rw — Session Request. In the absence ofUSBOTGSS_OEVT[9] OTGBDEVSESSVLDDETEVNT after a request, the application must wait for at least TB_SRP_FAIL (6 secs) before another request.
    0=noop (No action); 1=srp (Initiate the SRP (data line pulsing) on the USB.); 0=zero (All reads return zero.)
  [2] TERMSELDLPULSE rw — TermSelect Data Line Pulse. Alternate SRP data line pulsing method on UTMI interface.
    0=newEnum1 (utmi_txvalid used for SRP generation (default)); 1=newEnum2 (utmi_termselect used for SRP generation)
  [1] DEVSETHNPEN rw — Device Set HNP Enable. To be set when HNP has been successfully enabled by the connected host, using the SetFeature.SetHNPEnable command.
    0=dis (HNP disabled in device); 1=en (HNP enabled in device)
  [0] HSTSETHNPEN rw — Host Set HNP Enable. To be set when HNP has been successfully enabled on the connected device, using the SetFeature.SetHNPEnable command.
    0=dis (HNP disabled in host); 1=en (HNP enabled in host)
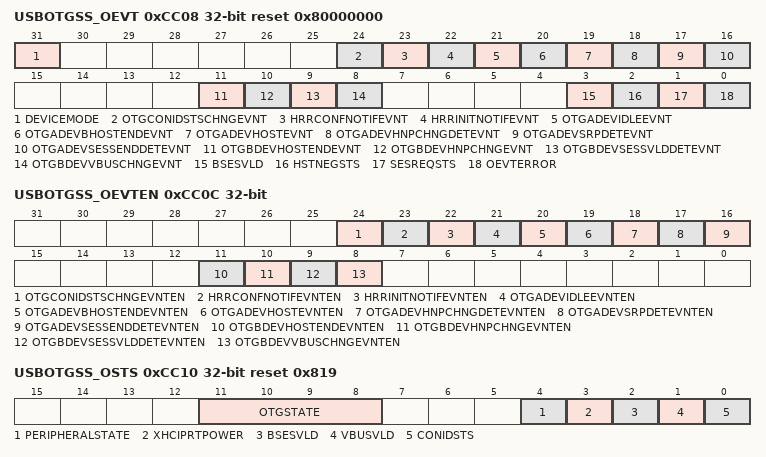
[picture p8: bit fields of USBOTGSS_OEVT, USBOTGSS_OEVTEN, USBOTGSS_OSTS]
0xCC08 USBOTGSS_OEVT access not given reset 0x80000000 — OTG event: OTG interrupt status. All writable bits are cleared by writing a 1.
  [31] DEVICEMODE ro — Dual-role device's mode, based on iddig input.
    1=b (B-device = default peripheral); 0=a (A-device = default host)
  [24] OTGCONIDSTSCHNGEVNT — Connector ID status change event. Set in both A-device and B-device mode. (access RW W1toClr)
    0=noop (No action); 1=clr (Clear the event); 1=evt (Event was set by core); 0=noevt (Event was not set)
  [23] HRRCONFNOTIFEVNT — Host Role Request Confirm Notifier Event. Set upon reception of HRR Device Notification TP with Confirm field set. Set in OTG3, SS, A-host or B-host mode only. OTG3: NOT IMPLEMENTED (access RW W1toClr)
    values as OTGCONIDSTSCHNGEVNT
  [22] HRRINITNOTIFEVNT — Host Role Request Initiate Notifier Event. Set upon reception of HRR Device Notification TP with Initiate field set. Set in OTG3, SS, A-host or B-host mode only. OTG3: NOT IMPLEMENTED (access RW W1toClr)
    values as OTGCONIDSTSCHNGEVNT
  [21] OTGADEVIDLEEVNT — A-device A-IDLE Event. Set when OTG FSM enters A-IDLE state from any other state. Set in A-device mode only. OTG3: NOT IMPLEMENTED (access RW W1toClr)
    values as OTGCONIDSTSCHNGEVNT
  [20] OTGADEVBHOSTENDEVNT — A-device B-host End Event. Set when connected B-device has completed its B-host role and returns to B-peripheral. Set in A-device mode only. (access RW W1toClr)
    values as OTGCONIDSTSCHNGEVNT
  [19] OTGADEVHOSTEVNT — A-device Host Event. Set when device enters host role, upon initial connect to B-device as well as upon HNP from A-peripheral to A-host. Set in A-device mode only. (access RW W1toClr)
    values as OTGCONIDSTSCHNGEVNT
  [18] OTGADEVHNPCHNGDETEVNT — A-device HNP change Detected Event. Set when there is an HNP event. Set in A-device mode only. (access RW W1toClr)
    values as OTGCONIDSTSCHNGEVNT
  [17] OTGADEVSRPDETEVNT — A-device SRP Detected Event. Set when SRP request from B-device is detected. Set in A-device mode only. (access RW W1toClr)
    values as OTGCONIDSTSCHNGEVNT
  [16] OTGADEVSESSENDDETEVNT — A-device Session End Detected Event. Set when UTMI input 'a-vbus-valid' is deasserted (0). Set in A-device mode only. (access RW W1toClr)
    values as OTGCONIDSTSCHNGEVNT
  [11] OTGBDEVHOSTENDEVNT — B-device Host End Event. Set completing B-host role and returning to default B-peripheral role. Set in B-device mode only. (access RW W1toClr)
    values as OTGCONIDSTSCHNGEVNT
  [10] OTGBDEVHNPCHNGEVNT — B-device HNP Change Event. Set upon (success of failure of an) HNP attempt. Set in B-device mode only. (access RW W1toClr)
    values as OTGCONIDSTSCHNGEVNT
  [9] OTGBDEVSESSVLDDETEVNT — B-device Session Valid Detected Event. Set when B-device succeeds in starting a session. Set in B-device mode only. (access RW W1toClr)
    values as OTGCONIDSTSCHNGEVNT
  [8] OTGBDEVVBUSCHNGEVNT — B-device VBUS Change Event. Set when UTMI input 'b-session-valid' transitions (to 0 or 1). Set in B-device mode only. (access RW W1toClr)
    values as OTGCONIDSTSCHNGEVNT
  [3] BSESVLD ro — B-Session Valid. Updated when OTGBDevVBUSChngEvnt is set.
    1=valid (B-session is valid on VBUS); 0=invalid (B-session is not valid on VBUS)
  [2] HSTNEGSTS ro — Host Negociation Status. Updated when OTGADevHNPChngEvnt or OTGBDevHNPChngEvnt is set.
    1=success (Host negotiation success.); 0=failure (Host negotiation failure. In A-device, indicates imminent end of session indication from core. In B-device, it indicates that the timer used to wait for an A-device to signal a connection (b_ase0_brst_tmout) timed out resulting in B-device staying as B-peripheral.)
  [1] SESREQSTS ro — Session Request Status. Updated when OTGBDevSessVldDetEvnt is set.
    1=SRP (Session started as a result of successful SRP.); 0=noSRP (Session not started as a result of SRP.)
  [0] OEVTERROR — No errors currently defined. (access RW W1toClr)
    values as OTGCONIDSTSCHNGEVNT
0xCC0C USBOTGSS_OEVTEN access per field — OTG event enable: OTG interrupt event enable.
  [all] fields
    0=dis (Event disabled); 1=en (Event enabled)
  [24] OTGCONIDSTSCHNGEVNTEN rw — Connector ID Status Change Event Enable.
  [23] HRRCONFNOTIFEVNTEN rw — Host Role Request Confirm Notifier Event Enable. OTG3: NOT IMPLEMENTED
  [22] HRRINITNOTIFEVNTEN rw — Host Role Request Initiate Notifier Event Enable. OTG3: NOT IMPLEMENTED
  [21] OTGADEVIDLEEVNTEN rw — A-device A-IDLE Event Enable.
  [20] OTGADEVBHOSTENDEVNTEN rw — A-device B-host End Event Enable.
  [19] OTGADEVHOSTEVNTEN rw — A-device Host Event Enable.
  [18] OTGADEVHNPCHNGDETEVNTEN rw — A-device HNP change Detected Event Enable.
  [17] OTGADEVSRPDETEVNTEN rw — A-device SRP Detected Event Enable.
  [16] OTGADEVSESSENDDETEVNTEN rw — A-device Session End Detected Event Enable.
  [11] OTGBDEVHOSTENDEVNTEN rw — B-device Host End Event Enable.
  [10] OTGBDEVHNPCHNGEVNTEN rw — B-device HNP Change Event Enable.
  [9] OTGBDEVSESSVLDDETEVNTEN rw — B-device Session Valid Detected Event Enable.
  [8] OTGBDEVVBUSCHNGEVNTEN rw — B-device VBUS Change Event Enable.
0xCC10 USBOTGSS_OSTS ro reset 0x819 — OTG status
  [11:8] OTGSTATE — [A-device and B-device] OTG state machine state, for debug. Default value can vary depending on integration.
    3=a_wait_vfall; 14=a_wait_switch; 12=b_wait_acon; 4=a_vbus_err; 11=b_peripheral; 15=b_wait_switch; 2=a_wait_bcon; 0=a_idle; 10=b_srp_init; 6=a_suspend; 1=a_wait_vrise; 8=a_wait_ppwr; 7=a_peripheral; 9=b_idle; 13=b_host; 5=a_host
  [4] PERIPHERALSTATE — [A-device and B-device] Current role of the controller
    1=Peripheral; 0=Host
  [3] XHCIPRTPOWER — [A-device] xHCI host port power. Reflects host bit fieldUSBOTGSS_PORTSC1/2[9] PP.
  [2] BSESVLD — [B-device] VBUS B-session valid status
    1=B-session_is_valid; 0=B-session_is_not_valid
  [1] VBUSVLD — [A-device] VBUS valid status
    1=VBUS_is_valid; 0=VBUS_is_not_valid
  [0] CONIDSTS — [A-device and B-device] Connector ID status. Default value can vary depending on integration.
    1=Core_is_B-device; 0=Core_is_A-device
